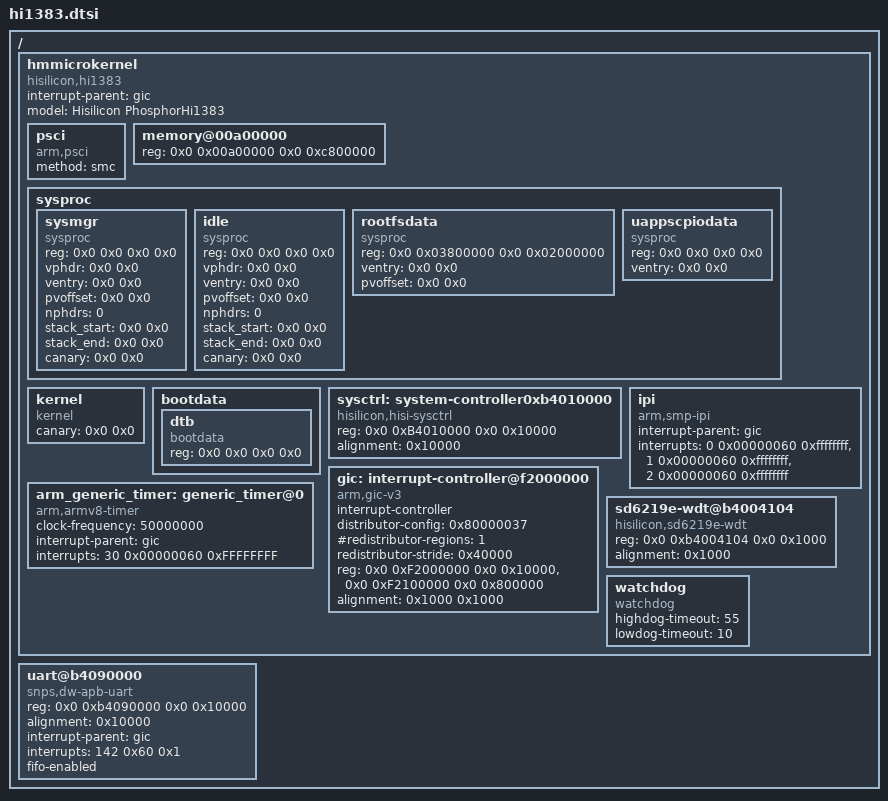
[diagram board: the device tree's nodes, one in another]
/*
 * Copyright (c) Huawei Technologies Co., Ltd. 2021. All rights reserved.
 * Description: Device tree for common hi1383
 * Author: Huawei OS Kernel Lab
 * Create: Tue Nov 30 16:16:08 2021
 */

/ {
	#address-cells = <2>;
	#size-cells = <2>;
	hmmicrokernel {
		#address-cells = <2>;
		#size-cells = <2>;
		interrupt-parent = <&gic>;

		model = "Hisilicon PhosphorHi1383";
		compatible = "hisilicon,hi1383";

		psci {
			compatible = "arm,psci";
			method = "smc";
		};

		memory@00a00000 {
			device_type = "memory";
			reg = <0x0 0x00a00000 0x0 0xc800000>; /* OS kernel */
		};

		sysproc {
			#address-cells = <2>;
			#size-cells = <2>;
			sysmgr {
				compatible = "sysproc", "sysmgr";
				/* filled by bootloader */
				reg      = <0x0 0x0 0x0 0x0>;
				vphdr    = <0x0 0x0>;
				ventry   = <0x0 0x0>;
				pvoffset = <0x0 0x0>;
				nphdrs   = <0>;
				stack_start = <0x0 0x0>;
				stack_end = <0x0 0x0>;
				canary = <0x0 0x0>;
			};
			idle {
				compatible = "sysproc", "idle";
				/* filled by bootloader */
				reg      = <0x0 0x0 0x0 0x0>;
				vphdr    = <0x0 0x0>;
				ventry   = <0x0 0x0>;
				pvoffset = <0x0 0x0>;
				nphdrs   = <0>;
				stack_start = <0x0 0x0>;
				stack_end = <0x0 0x0>;
				canary = <0x0 0x0>;
			};
			/* Describe board boot param rootfs in top level dts */
			rootfsdata {
				compatible = "sysproc", "rootfs";
				reg = <0x0 0x03800000 0x0 0x02000000>;
				ventry = <0x0 0x0>;
				/* filled by bootloader */
				pvoffset = <0x0 0x0>;
			};
			/*
			 * Describe uappscpio param in dts, which will be edited by elfloader_ng
			 * after uapps.cpio is loaded, provide for loading uapps
			 */
			uappscpiodata {
				compatible = "sysproc", "uappscpio";
				/* filled by bootloader */
				reg      = <0x0 0x0 0x0 0x0>;
				ventry   = <0x0 0x0>;
			};
		};

		kernel {
			compatible = "kernel";
			/* filled by bootloader */
			canary = <0x0 0x0>;
		};

		bootdata {
			#address-cells = <2>;
			#size-cells = <2>;
			dtb {
				compatible = "bootdata", "dtb";
				/* filled by bootloader */
				reg = <0x0 0x0 0x0 0x0>;
			};
		};

		sysctrl: system-controller0xb4010000 {
			compatible = "hisilicon,hisi-sysctrl", "syscon";
                        reg = <0x0 0xB4010000 0x0 0x10000>;
			alignment = <0x10000>;
		};

		gic: interrupt-controller@f2000000 {
			compatible = "arm,gic-v3";
			#interrupt-cells = <3>;
			interrupt-controller;

			/* Enable group 0, Group1NS, Group1S, ARE_NS, ARE_S,
			 * Split EOI and Deactive Mode */
			distributor-config = <0x80000037>;

			#redistributor-regions = <1>;
			redistributor-stride = <0x40000>;

			reg = <0x0 0xF2000000 0x0 0x10000>,  /* GICD */
			      <0x0 0xF2100000 0x0 0x800000>; /* GICR 16 CORE */
			alignment = <0x1000 0x1000>;
		};

		arm_generic_timer: generic_timer@0 {
			compatible = "arm,armv8-timer";
			clock-frequency = <50000000>;

			/* interrupt settings */
			interrupt-parent = <&gic>;

			/* PPI 30: Non-secure physical timer
			 * level triggered, hwprio:60 */
			interrupts = <30 0x00000060 0xFFFFFFFF>;
		};

		ipi {
			/* smp ipi */
			compatible = "arm,smp-ipi";

			interrupt-parent = <&gic>;

			/* interrupt settings:
			 * 1st cell: real hardware irq number
			 *     ARM recommendation: ID 0-7 for Non-Secure;
			 *                         ID 8-15 for Secure Interrupt
			 * 2nd cell: interrupt config
			 *     bit [27:26]: Group setting
			 *     bit [24]: Trigger Type
			 *     bit [23:8]: reserved
			 *     bit [7:0]: Priority
			 * 3rd cell: interrupt target config
			 *     support a maximum 8 CPUs.
			 */
			interrupts = <0 0x00000060 0xffffffff>, /* IPI_RESCHEDULE */
				     <1 0x00000060 0xffffffff>, /* IPI_CALL_FUNC */
				     <2 0x00000060 0xffffffff>; /* IPI_CPU_STOP */
		};

		/* Hi1383 CPU use same watchdog as sd6219e */
		sd6219e-wdt@b4004104 {
			compatible = "hisilicon,sd6219e-wdt";
			#address-cells = <2>;
			#size-cells = <2>;

			reg = <0x0 0xb4004104 0x0 0x1000>;
			alignment = <0x1000>;
		};

                watchdog {
                        compatible = "watchdog";
                        /* reserve 55ms for hguard to take over the watchdog */
                        highdog-timeout = <55>;
                        /* reserve 10ms for subcore to be pulled up*/
                        lowdog-timeout = <10>;
                };
	};


	/* For kernel uart driver */
	uart@b4090000 {
		compatible = "snps,dw-apb-uart", "arm,dw8250,uart";
		reg = <0x0 0xb4090000 0x0 0x10000>;
		alignment = <0x10000>;

		interrupt-parent = <&gic>;
		/* priority 2, level-triggered, target cpu 0 */
		interrupts = <142 0x60 0x1>;
		/* enable fifo */
		fifo-enabled;
	};
};
